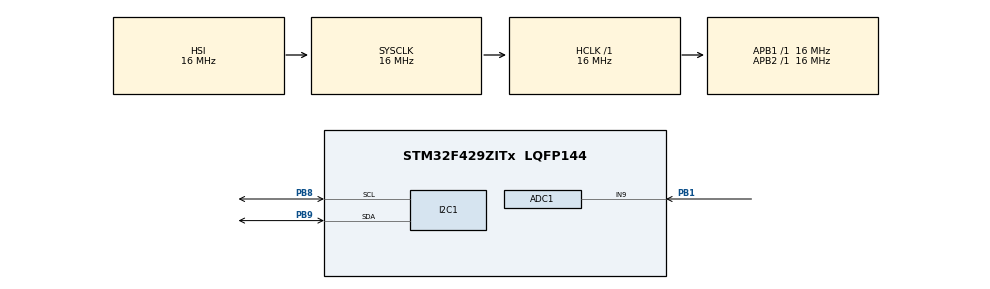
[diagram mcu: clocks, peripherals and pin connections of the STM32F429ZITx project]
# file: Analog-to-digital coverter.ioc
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ADC1.Channel-1\#ChannelRegularConversion=ADC_CHANNEL_9
ADC1.NbrOfConversion=1
ADC1.NbrOfConversionFlag=1
ADC1.Rank-1\#ChannelRegularConversion=1
ADC1.SamplingTime-1\#ChannelRegularConversion=ADC_SAMPLETIME_3CYCLES
ADC1.ScanConvMode=DISABLE
ADC1.master=1
I2C1.I2C_Mode=I2C_Fast
Mcu.Family=STM32F4
Mcu.Name=STM32F429ZITx
Mcu.Package=LQFP144
NVIC.PriorityGroup=NVIC_PRIORITYGROUP_4
PB1.Signal=ADCx_IN9
PB8.Mode=I2C
PB8.Signal=I2C1_SCL
PB9.Mode=I2C
PB9.Signal=I2C1_SDA
ProjectManager.HeapSize=0x200
ProjectManager.StackSize=0x400
ProjectManager.TargetToolchain=STM32CubeIDE
RCC.AHBFreq_Value=16000000
RCC.APB1Freq_Value=16000000
RCC.APB2Freq_Value=16000000
RCC.CortexFreq_Value=16000000
RCC.HSE_VALUE=25000000
RCC.HSI_VALUE=16000000
RCC.LSE_VALUE=32768
RCC.SYSCLKFreq_VALUE=16000000
RCC.VCOOutputFreq_Value=192000000
SH.ADCx_IN9.0=ADC1_IN9,IN9
board=custom

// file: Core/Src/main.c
/* USER CODE BEGIN Header */
/**
  ******************************************************************************
  * @file           : main.c
  * @brief          : Main program body
  ******************************************************************************
  * @attention
  *
  * Copyright (c) 2024 STMicroelectronics.
  * All rights reserved.
  *
  * This software is licensed under terms that can be found in the LICENSE file
  * in the root directory of this software component.
  * If no LICENSE file comes with this software, it is provided AS-IS.
  *
  ******************************************************************************
  */
/* USER CODE END Header */
#include "main.h"
#include "adc.h"
#include "i2c.h"
#include "gpio.h"

/* USER CODE BEGIN Includes */
#include "oled.h"
/* USER CODE END Includes */

void SystemClock_Config(void);

int main(void)
{

  /* MCU Configuration--------------------------------------------------------*/

  /* Reset of all peripherals, Initializes the Flash interface and the Systick. */
  HAL_Init();

  /* Configure the system clock */
  SystemClock_Config();

  /* Initialize all configured peripherals */
  MX_GPIO_Init();
  MX_ADC1_Init();
  MX_I2C1_Init();
  /* USER CODE BEGIN 2 */
  HAL_Delay(20);
  OLED_Init();
  OLED_ShowString(0, 0, "AD: ", &Font_11x18);
  OLED_ShowString(0, 25, "Volt: ", &Font_11x18);
  OLED_ShowString(82, 25, ".", &Font_11x18);
  HAL_ADC_Start(&hadc1);
  uint32_t ADValue = 0;
  float Voltage = 0;

  /* USER CODE END 2 */

  /* Infinite loop */
  /* USER CODE BEGIN WHILE */
  while (1)
  {
	  HAL_ADC_Start(&hadc1);
	  HAL_ADC_PollForConversion(&hadc1, HAL_MAX_DELAY);
	  ADValue =  HAL_ADC_GetValue(&hadc1);
	  Voltage = (float) ADValue / 4095 * 3.3;
	  OLED_ShowNum_Fill_Zero(70, 0, 4, ADValue, &Font_11x18);
	  OLED_ShowNum_Fill_Zero(70, 25, 1, Voltage, &Font_11x18);
	  OLED_ShowNum(93, 25, (int)(Voltage * 100) % 100, &Font_11x18);
	  HAL_Delay(100);
//	  OLED_ShowNum(0, 20, ADValue, &Font_11x18);
    /* USER CODE END WHILE */

  }
}

void SystemClock_Config(void)
{
  RCC_OscInitTypeDef RCC_OscInitStruct = {0};
  RCC_ClkInitTypeDef RCC_ClkInitStruct = {0};

  /** Configure the main internal regulator output voltage
  */
  __HAL_RCC_PWR_CLK_ENABLE();
  __HAL_PWR_VOLTAGESCALING_CONFIG(PWR_REGULATOR_VOLTAGE_SCALE3);

  /** Initializes the RCC Oscillators according to the specified parameters
  * in the RCC_OscInitTypeDef structure.
  */
  RCC_OscInitStruct.OscillatorType = RCC_OSCILLATORTYPE_HSI;
  RCC_OscInitStruct.HSIState = RCC_HSI_ON;
  RCC_OscInitStruct.HSICalibrationValue = RCC_HSICALIBRATION_DEFAULT;
  RCC_OscInitStruct.PLL.PLLState = RCC_PLL_NONE;
  if (HAL_RCC_OscConfig(&RCC_OscInitStruct) != HAL_OK)
  {
    Error_Handler();
  }

  /** Initializes the CPU, AHB and APB buses clocks
  */
  RCC_ClkInitStruct.ClockType = RCC_CLOCKTYPE_HCLK|RCC_CLOCKTYPE_SYSCLK
                              |RCC_CLOCKTYPE_PCLK1|RCC_CLOCKTYPE_PCLK2;
  RCC_ClkInitStruct.SYSCLKSource = RCC_SYSCLKSOURCE_HSI;
  RCC_ClkInitStruct.AHBCLKDivider = RCC_SYSCLK_DIV1;
  RCC_ClkInitStruct.APB1CLKDivider = RCC_HCLK_DIV1;
  RCC_ClkInitStruct.APB2CLKDivider = RCC_HCLK_DIV1;

  if (HAL_RCC_ClockConfig(&RCC_ClkInitStruct, FLASH_LATENCY_0) != HAL_OK)
  {
    Error_Handler();
  }
}

void Error_Handler(void)
{
  __disable_irq();
  while (1)
  {
  }
}
